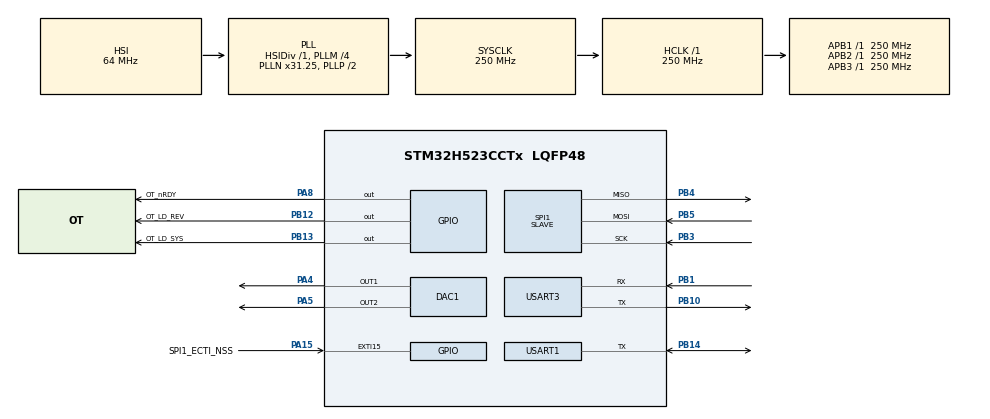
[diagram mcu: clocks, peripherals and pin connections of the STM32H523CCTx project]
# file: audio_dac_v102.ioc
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BOOTPATH.BootPathName=LEGACY
BOOTPATH.UserSelectedBootPath=LEGACY
CORTEX_M33_NS.AccessPermission-Cortex_Memory_Protection_Unit_Region0_Settings=MPU_REGION_ALL_RW
CORTEX_M33_NS.Attributes0=MPU_ATTRIBUTES_NUMBER0
CORTEX_M33_NS.BaseAddress-Cortex_Memory_Protection_Unit_Region0_Settings=0x2003C000
CORTEX_M33_NS.DisableExec-Cortex_Memory_Protection_Unit_Region0_Settings=MPU_INSTRUCTION_ACCESS_DISABLE
CORTEX_M33_NS.Enable-Cortex_Memory_Protection_Unit_Region0_Settings=MPU_REGION_ENABLE
CORTEX_M33_NS.IsShareable-Cortex_Memory_Protection_Unit_Region0_Settings=MPU_ACCESS_INNER_SHAREABLE
CORTEX_M33_NS.LimitAddress-Cortex_Memory_Protection_Unit_Region0_Settings=0x20043FFF
CORTEX_M33_NS.MPU_Control=MPU_PRIVILEGED_DEFAULT
CORTEX_M33_NS.userName=CORTEX_M33
DAC1.DAC_Channel-DAC_OUT1_Ext=DAC_CHANNEL_1
DAC1.DAC_Channel-DAC_OUT2_Ext=DAC_CHANNEL_2
DAC1.DAC_HighFrequency=DAC_HIGH_FREQUENCY_INTERFACE_MODE_DISABLE
DAC1.DAC_Trigger-DAC_OUT1_Ext=DAC_TRIGGER_T1_TRGO
DAC1.DAC_Trigger-DAC_OUT2_Ext=DAC_TRIGGER_T7_TRGO
GPDMA1.CIRCULARMODE_GPDMACH0=ENABLE
GPDMA1.CIRCULARMODE_GPDMACH2=ENABLE
GPDMA1.CIRCULARMODE_GPDMACH4=DISABLE
GPDMA1.DESTINC_GPDMACH0=DMA_DINC_INCREMENTED
GPDMA1.DESTINC_GPDMACH4=DMA_DINC_INCREMENTED
GPDMA1.DIRECTION_GPDMACH1=DMA_MEMORY_TO_PERIPH
GPDMA1.DIRECTION_GPDMACH5=DMA_MEMORY_TO_PERIPH
GPDMA1.IPHANDLE_GPDMACH0-SIMPLEREQUEST_GPDMACH0=__NULL
GPDMA1.IPHANDLE_GPDMACH1-SIMPLEREQUEST_GPDMACH1=__NULL
GPDMA1.IPHANDLE_GPDMACH2-SIMPLEREQUEST_GPDMACH2=__NULL
GPDMA1.IPHANDLE_GPDMACH3-SIMPLEREQUEST_GPDMACH3=__NULL
GPDMA1.IPHANDLE_GPDMACH4-SIMPLEREQUEST_GPDMACH4=__NULL
GPDMA1.IPHANDLE_GPDMACH5-SIMPLEREQUEST_GPDMACH5=__NULL
GPDMA1.REQUEST_GPDMACH0=GPDMA1_REQUEST_USART3_RX
GPDMA1.REQUEST_GPDMACH1=GPDMA1_REQUEST_USART3_TX
GPDMA1.REQUEST_GPDMACH2=GPDMA1_REQUEST_USART1_RX
GPDMA1.REQUEST_GPDMACH3=GPDMA1_REQUEST_USART1_TX
GPDMA1.REQUEST_GPDMACH4=GPDMA1_REQUEST_SPI1_RX
GPDMA1.REQUEST_GPDMACH5=GPDMA1_REQUEST_SPI1_TX
GPDMA1.SRCINC_GPDMACH1=DMA_SINC_INCREMENTED
GPDMA1.SRCINC_GPDMACH5=DMA_SINC_INCREMENTED
GPDMA2.CIRCULARMODE_GPDMACH0=ENABLE
GPDMA2.CIRCULARMODE_GPDMACH1=ENABLE
GPDMA2.DESTDATAWIDTH_GPDMACH0=DMA_DEST_DATAWIDTH_WORD
GPDMA2.DESTDATAWIDTH_GPDMACH1=DMA_DEST_DATAWIDTH_WORD
GPDMA2.DIRECTION_GPDMACH0=DMA_MEMORY_TO_PERIPH
GPDMA2.DIRECTION_GPDMACH1=DMA_MEMORY_TO_PERIPH
GPDMA2.IPHANDLE_GPDMACH0-SIMPLEREQUEST_GPDMACH0=__NULL
GPDMA2.IPHANDLE_GPDMACH1-SIMPLEREQUEST_GPDMACH1=__NULL
GPDMA2.LINKALLOCATEDPORT_CIRCULAR_GPDMACH0=DMA_LINK_ALLOCATED_PORT1
GPDMA2.LINKALLOCATEDPORT_CIRCULAR_GPDMACH1=DMA_LINK_ALLOCATED_PORT1
GPDMA2.PRIORITY_LL_CIRCULAR_GPDMACH0=DMA_LOW_PRIORITY_HIGH_WEIGHT
GPDMA2.PRIORITY_LL_CIRCULAR_GPDMACH1=DMA_LOW_PRIORITY_HIGH_WEIGHT
GPDMA2.REQUEST_GPDMACH0=GPDMA2_REQUEST_DAC1_CH1
GPDMA2.REQUEST_GPDMACH1=GPDMA2_REQUEST_DAC1_CH2
GPDMA2.SRCDATAWIDTH_GPDMACH0=DMA_SRC_DATAWIDTH_HALFWORD
GPDMA2.SRCDATAWIDTH_GPDMACH1=DMA_SRC_DATAWIDTH_HALFWORD
GPDMA2.SRCINC_GPDMACH0=DMA_SINC_INCREMENTED
GPDMA2.SRCINC_GPDMACH1=DMA_SINC_INCREMENTED
GPDMA2.TRANSFERALLOCATEDPORTSRC_GPDMACH0=DMA_SRC_ALLOCATED_PORT1
GPDMA2.TRANSFERALLOCATEDPORTSRC_GPDMACH1=DMA_SRC_ALLOCATED_PORT1
Mcu.Family=STM32H5
Mcu.Name=STM32H523CCTx
Mcu.Package=LQFP48
NVIC.EXTI15_IRQn=true\:0\:0\:false\:false\:true\:true\:true\:true
NVIC.GPDMA1_Channel0_IRQn=true\:2\:0\:true\:false\:true\:false\:true\:true
NVIC.GPDMA1_Channel1_IRQn=true\:2\:0\:true\:false\:true\:false\:true\:true
NVIC.GPDMA1_Channel2_IRQn=true\:2\:0\:true\:false\:true\:false\:true\:true
NVIC.GPDMA1_Channel3_IRQn=true\:2\:0\:true\:false\:true\:false\:true\:true
NVIC.GPDMA1_Channel4_IRQn=true\:2\:0\:true\:false\:true\:false\:true\:true
NVIC.GPDMA1_Channel5_IRQn=true\:2\:0\:true\:false\:true\:false\:true\:true
NVIC.GPDMA2_Channel0_IRQn=true\:0\:0\:false\:false\:true\:false\:true\:true
NVIC.GPDMA2_Channel1_IRQn=true\:0\:0\:false\:false\:true\:false\:true\:true
NVIC.PriorityGroup=NVIC_PRIORITYGROUP_4
NVIC.SPI1_IRQn=true\:1\:0\:true\:false\:true\:true\:true\:true
NVIC.TIM7_IRQn=true\:2\:0\:true\:false\:true\:true\:true\:true
NVIC.USART1_IRQn=true\:1\:0\:true\:false\:true\:true\:true\:true
NVIC.USART3_IRQn=true\:1\:0\:true\:false\:true\:true\:true\:true
PA13(JTMS/SWDIO).Mode=Serial_Wire
PA13(JTMS/SWDIO).Signal=DEBUG_JTMS-SWDIO
PA14(JTCK/SWCLK).Mode=Serial_Wire
PA14(JTCK/SWCLK).Signal=DEBUG_JTCK-SWCLK
PA15(JTDI).GPIO_Label=SPI1_ECTI_NSS
PA15(JTDI).GPIO_ModeDefaultEXTI=GPIO_MODE_IT_RISING_FALLING
PA15(JTDI).Signal=GPXTI15
PA4.Signal=COMP_DAC11_group
PA5.Signal=COMP_DAC12_group
PA8.GPIO_Label=OT_nRDY
PA8.PinState=GPIO_PIN_SET
PA8.Signal=GPIO_Output
PB1.GPIO_PuPd=GPIO_PULLUP
PB1.Mode=Asynchronous
PB1.Signal=USART3_RX
PB10.GPIO_PuPd=GPIO_PULLUP
PB10.Mode=Asynchronous
PB10.Signal=USART3_TX
PB12.GPIO_Label=OT_LD_REV
PB12.Signal=GPIO_Output
PB13.GPIO_Label=OT_LD_SYS
PB13.Signal=GPIO_Output
PB14.GPIO_PuPd=GPIO_PULLUP
PB14.Mode=Half_duplex(single_wire_mode)
PB14.Signal=USART1_TX
PB3(JTDO/TRACESWO).Mode=Full_Duplex_Slave
PB3(JTDO/TRACESWO).Signal=SPI1_SCK
PB4(NJTRST).Mode=Full_Duplex_Slave
PB4(NJTRST).Signal=SPI1_MISO
PB5.Mode=Full_Duplex_Slave
PB5.Signal=SPI1_MOSI
ProjectManager.HeapSize=0x2000
ProjectManager.StackSize=0x2000
ProjectManager.TargetToolchain=STM32CubeIDE
RCC.ADCFreq_Value=250000000
RCC.AHBFreq_Value=250000000
RCC.APB1Freq_Value=250000000
RCC.APB1TimFreq_Value=250000000
RCC.APB2Freq_Value=250000000
RCC.APB2TimFreq_Value=250000000
RCC.APB3Freq_Value=250000000
RCC.CSI_VALUE=4000000
RCC.CortexFreq_Value=250000000
RCC.DACLowPowerCLockSelection=RCC_DACLPCLKSOURCE_LSI
RCC.EPOD_VALUE=64000000
RCC.HCLKFreq_Value=250000000
RCC.HSE_VALUE=25000000
RCC.HSI48_VALUE=48000000
RCC.HSIDiv=RCC_HSI_DIV1
RCC.HSI_VALUE=64000000
RCC.LSE_VALUE=32768
RCC.LSIRC_VALUE=32000
RCC.PLL2M=8
RCC.PLL2N=64
RCC.PLL2Source=RCC_PLL2_SOURCE_HSI
RCC.PLL3M=8
RCC.PLL3N=32
RCC.PLL3P=4
RCC.PLL3Q=4
RCC.PLL3Source=RCC_PLL3_SOURCE_HSI
RCC.PLLFRACN=2048
RCC.PLLM=4
RCC.PLLN=31
RCC.PLLSourceVirtual=RCC_PLL1_SOURCE_HSI
RCC.SPI1CLockSelection=RCC_SPI1CLKSOURCE_PLL3P
RCC.SYSCLKFreq_VALUE=250000000
RCC.SYSCLKSource=RCC_SYSCLKSOURCE_PLLCLK
RCC.USBFreq_Value=48000000
RCC.VCOOutputFreq_Value=500000000
SH.COMP_DAC11_group.0=DAC1_OUT1,DAC_OUT1_Ext
SH.COMP_DAC12_group.0=DAC1_OUT2,DAC_OUT2_Ext
SPI1.DataSize=SPI_DATASIZE_8BIT
SPI1.Direction=SPI_DIRECTION_2LINES
SPI1.FifoThreshold=SPI_FIFO_THRESHOLD_01DATA
SPI1.Mode=SPI_MODE_SLAVE
SPI1.VirtualType=VM_SLAVE
TIM1.PeriodNoDither=7811
TIM1.TIM_MasterOutputTrigger=TIM_TRGO_UPDATE
TIM7.AutoReloadPreload=TIM_AUTORELOAD_PRELOAD_DISABLE
TIM7.PeriodNoDither=7811
TIM7.Prescaler=0
TIM7.TIM_MasterOutputTrigger=TIM_TRGO_UPDATE
USART1.VirtualMode-Half_duplex(single_wire_mode)=VM_ASYNC
USART3.VirtualMode-Asynchronous=VM_ASYNC
VP_BOOTPATH_VS_BOOTPATH.Mode=BP_Activate
VP_CORTEX_M33_NS_VS_Hclk.Mode=Hclk_Mode
VP_DCACHE1_VS_DCACHE.Mode=DCACHE_Activate
VP_GPDMA1_VS_GPDMACH0.Mode=SIMPLEREQUEST_GPDMACH0
VP_GPDMA1_VS_GPDMACH1.Mode=SIMPLEREQUEST_GPDMACH1
VP_GPDMA1_VS_GPDMACH2.Mode=SIMPLEREQUEST_GPDMACH2
VP_GPDMA1_VS_GPDMACH3.Mode=SIMPLEREQUEST_GPDMACH3
VP_GPDMA1_VS_GPDMACH4.Mode=SIMPLEREQUEST_GPDMACH4
VP_GPDMA1_VS_GPDMACH5.Mode=SIMPLEREQUEST_GPDMACH5
VP_GPDMA2_VS_GPDMACH0.Mode=SIMPLEREQUEST_GPDMACH0
VP_GPDMA2_VS_GPDMACH1.Mode=SIMPLEREQUEST_GPDMACH1
VP_ICACHE_VS_ICACHE.Mode=DefaultMode
VP_MEMORYMAP_VS_MEMORYMAP.Mode=CurAppReg
VP_PWR_VS_LPOM.Mode=PowerOptimisation
VP_PWR_VS_SECSignals.Mode=Security/Privilege
VP_TIM1_VS_ClockSourceINT.Mode=Internal
VP_TIM7_VS_ClockSourceINT.Mode=Enable_Timer
board=custom

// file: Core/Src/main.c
/* USER CODE BEGIN Header */
/**
  ******************************************************************************
  * @file           : main.c
  * @brief          : Main program body
  ******************************************************************************
  * @attention
  *
  * Copyright (c) 2025 STMicroelectronics.
  * All rights reserved.
  *
  * This software is licensed under terms that can be found in the LICENSE file
  * in the root directory of this software component.
  * If no LICENSE file comes with this software, it is provided AS-IS.
  *
  ******************************************************************************
  */
/* USER CODE END Header */
#include "main.h"

/* USER CODE BEGIN Includes */
#include "stdio.h"
#include "user_def.h"
/* USER CODE END Includes */

DAC_HandleTypeDef hdac1;
DMA_NodeTypeDef Node_GPDMA2_Channel1;
DMA_QListTypeDef List_GPDMA2_Channel1;
DMA_HandleTypeDef handle_GPDMA2_Channel1;
DMA_NodeTypeDef Node_GPDMA2_Channel0;
DMA_QListTypeDef List_GPDMA2_Channel0;
DMA_HandleTypeDef handle_GPDMA2_Channel0;

DCACHE_HandleTypeDef hdcache1;

SPI_HandleTypeDef hspi1;
DMA_HandleTypeDef handle_GPDMA1_Channel5;
DMA_HandleTypeDef handle_GPDMA1_Channel4;

TIM_HandleTypeDef htim1;
TIM_HandleTypeDef htim7;

UART_HandleTypeDef huart1;
UART_HandleTypeDef huart3;
DMA_HandleTypeDef handle_GPDMA1_Channel3;
DMA_NodeTypeDef Node_GPDMA1_Channel2;
DMA_QListTypeDef List_GPDMA1_Channel2;
DMA_HandleTypeDef handle_GPDMA1_Channel2;
DMA_HandleTypeDef handle_GPDMA1_Channel1;
DMA_NodeTypeDef Node_GPDMA1_Channel0;
DMA_QListTypeDef List_GPDMA1_Channel0;
DMA_HandleTypeDef handle_GPDMA1_Channel0;

void SystemClock_Config(void);
static void MPU_Config(void);
static void MX_GPIO_Init(void);
static void MX_GPDMA1_Init(void);
static void MX_GPDMA2_Init(void);
static void MX_DAC1_Init(void);
static void MX_DCACHE1_Init(void);
static void MX_ICACHE_Init(void);
static void MX_SPI1_Init(void);
static void MX_USART3_UART_Init(void);
static void MX_USART1_UART_Init(void);
static void MX_TIM7_Init(void);
static void MX_TIM1_Init(void);

int main(void)
{

  /* USER CODE BEGIN 1 */
  // MPU disabled - causes SPI reception issues
  /* USER CODE END 1 */

  /* MCU Configuration--------------------------------------------------------*/

  /* MPU Configuration--------------------------------------------------------*/
  MPU_Config();

  /* Reset of all peripherals, Initializes the Flash interface and the Systick. */
  HAL_Init();

  /* Configure the system clock */
  SystemClock_Config();

  /* Initialize all configured peripherals */
  MX_GPIO_Init();
  MX_GPDMA1_Init();
  MX_GPDMA2_Init();
  MX_DAC1_Init();
  MX_DCACHE1_Init();
  MX_ICACHE_Init();
  MX_SPI1_Init();
  MX_USART3_UART_Init();
  MX_USART1_UART_Init();
  MX_TIM7_Init();
  MX_TIM1_Init();
  /* USER CODE BEGIN 2 */
  run_proc();

  /* USER CODE END 2 */

  /* Infinite loop */
  while (1)
  {

  }
}

void SystemClock_Config(void)
{
  RCC_OscInitTypeDef RCC_OscInitStruct = {0};
  RCC_ClkInitTypeDef RCC_ClkInitStruct = {0};

  /** Configure the main internal regulator output voltage
  */
  __HAL_PWR_VOLTAGESCALING_CONFIG(PWR_REGULATOR_VOLTAGE_SCALE0);

  while(!__HAL_PWR_GET_FLAG(PWR_FLAG_VOSRDY)) {}

  /** Initializes the RCC Oscillators according to the specified parameters
  * in the RCC_OscInitTypeDef structure.
  */
  RCC_OscInitStruct.OscillatorType = RCC_OSCILLATORTYPE_HSI|RCC_OSCILLATORTYPE_LSI;
  RCC_OscInitStruct.HSIState = RCC_HSI_ON;
  RCC_OscInitStruct.HSIDiv = RCC_HSI_DIV1;
  RCC_OscInitStruct.HSICalibrationValue = RCC_HSICALIBRATION_DEFAULT;
  RCC_OscInitStruct.LSIState = RCC_LSI_ON;
  RCC_OscInitStruct.PLL.PLLState = RCC_PLL_ON;
  RCC_OscInitStruct.PLL.PLLSource = RCC_PLL1_SOURCE_HSI;
  RCC_OscInitStruct.PLL.PLLM = 4;
  RCC_OscInitStruct.PLL.PLLN = 31;
  RCC_OscInitStruct.PLL.PLLP = 2;
  RCC_OscInitStruct.PLL.PLLQ = 2;
  RCC_OscInitStruct.PLL.PLLR = 2;
  RCC_OscInitStruct.PLL.PLLRGE = RCC_PLL1_VCIRANGE_3;
  RCC_OscInitStruct.PLL.PLLVCOSEL = RCC_PLL1_VCORANGE_WIDE;
  RCC_OscInitStruct.PLL.PLLFRACN = 2048;
  if (HAL_RCC_OscConfig(&RCC_OscInitStruct) != HAL_OK)
  {
    Error_Handler();
  }

  /** Initializes the CPU, AHB and APB buses clocks
  */
  RCC_ClkInitStruct.ClockType = RCC_CLOCKTYPE_HCLK|RCC_CLOCKTYPE_SYSCLK
                              |RCC_CLOCKTYPE_PCLK1|RCC_CLOCKTYPE_PCLK2
                              |RCC_CLOCKTYPE_PCLK3;
  RCC_ClkInitStruct.SYSCLKSource = RCC_SYSCLKSOURCE_PLLCLK;
  RCC_ClkInitStruct.AHBCLKDivider = RCC_SYSCLK_DIV1;
  RCC_ClkInitStruct.APB1CLKDivider = RCC_HCLK_DIV1;
  RCC_ClkInitStruct.APB2CLKDivider = RCC_HCLK_DIV1;
  RCC_ClkInitStruct.APB3CLKDivider = RCC_HCLK_DIV1;

  if (HAL_RCC_ClockConfig(&RCC_ClkInitStruct, FLASH_LATENCY_5) != HAL_OK)
  {
    Error_Handler();
  }

  /** Configure the programming delay
  */
  __HAL_FLASH_SET_PROGRAM_DELAY(FLASH_PROGRAMMING_DELAY_2);
}

static void MX_DAC1_Init(void)
{

  DAC_ChannelConfTypeDef sConfig = {0};

  /* USER CODE BEGIN DAC1_Init 1 */
  sConfig.DAC_OutputBuffer = DAC_OUTPUTBUFFER_ENABLE;

  /* USER CODE END DAC1_Init 1 */

  /** DAC Initialization
  */
  hdac1.Instance = DAC1;
  if (HAL_DAC_Init(&hdac1) != HAL_OK)
  {
    Error_Handler();
  }

  /** DAC channel OUT1 config
  */
  sConfig.DAC_HighFrequency = DAC_HIGH_FREQUENCY_INTERFACE_MODE_AUTOMATIC;
  sConfig.DAC_DMADoubleDataMode = DISABLE;
  sConfig.DAC_SignedFormat = DISABLE;
  sConfig.DAC_SampleAndHold = DAC_SAMPLEANDHOLD_DISABLE;
  sConfig.DAC_Trigger = DAC_TRIGGER_T1_TRGO;
  sConfig.DAC_OutputBuffer = DAC_OUTPUTBUFFER_ENABLE;
  sConfig.DAC_ConnectOnChipPeripheral = DAC_CHIPCONNECT_EXTERNAL;
  sConfig.DAC_UserTrimming = DAC_TRIMMING_FACTORY;
  if (HAL_DAC_ConfigChannel(&hdac1, &sConfig, DAC_CHANNEL_1) != HAL_OK)
  {
    Error_Handler();
  }

  /** DAC channel OUT2 config
  */
  sConfig.DAC_HighFrequency = DAC_HIGH_FREQUENCY_INTERFACE_MODE_AUTOMATIC;
  sConfig.DAC_DMADoubleDataMode = DISABLE;
  sConfig.DAC_SignedFormat = DISABLE;
  sConfig.DAC_SampleAndHold = DAC_SAMPLEANDHOLD_DISABLE;
  // DAC CH2 uses TIM7 TRGO trigger
  sConfig.DAC_Trigger = DAC_TRIGGER_T7_TRGO;  // TSEL=6 → TIM7 TRGO
  sConfig.DAC_OutputBuffer = DAC_OUTPUTBUFFER_ENABLE;
  sConfig.DAC_ConnectOnChipPeripheral = DAC_CHIPCONNECT_EXTERNAL;
  sConfig.DAC_UserTrimming = DAC_TRIMMING_FACTORY;
  if (HAL_DAC_ConfigChannel(&hdac1, &sConfig, DAC_CHANNEL_2) != HAL_OK)
  {
    Error_Handler();
  }

  /* USER CODE BEGIN DAC1_Init 1.5 */
  // INDEPENDENT DAC MODE: Each channel has its own DMA and trigger
  // DAC1: TEN1=1, DMAEN1=1, TSEL1=0 (TIM1_TRGO)
  // DAC2: TEN2=1, DMAEN2=1, TSEL2=6 (TIM7_TRGO)
  // Both channels operate independently with their own sample rates

  printf("[DAC_INIT] INDEPENDENT MODE: CH1=TIM1, CH2=TIM7, CR=0x%08lX\r\n", DAC1->CR);
  /* USER CODE END DAC1_Init 1.5 */
  /* USER CODE BEGIN DAC1_Init 2 */

  // NOTE: Calibration is performed in user_def.c init_proc() after UART init

  /* USER CODE END DAC1_Init 2 */

}

static void MX_DCACHE1_Init(void)
{

  hdcache1.Instance = DCACHE1;
  hdcache1.Init.ReadBurstType = DCACHE_READ_BURST_WRAP;
  if (HAL_DCACHE_Init(&hdcache1) != HAL_OK)
  {
    Error_Handler();
  }

}

static void MX_GPDMA1_Init(void)
{

  /* Peripheral clock enable */
  __HAL_RCC_GPDMA1_CLK_ENABLE();

  /* GPDMA1 interrupt Init */
    HAL_NVIC_SetPriority(GPDMA1_Channel0_IRQn, 2, 0);
    HAL_NVIC_EnableIRQ(GPDMA1_Channel0_IRQn);
    HAL_NVIC_SetPriority(GPDMA1_Channel1_IRQn, 2, 0);
    HAL_NVIC_EnableIRQ(GPDMA1_Channel1_IRQn);
    HAL_NVIC_SetPriority(GPDMA1_Channel2_IRQn, 2, 0);
    HAL_NVIC_EnableIRQ(GPDMA1_Channel2_IRQn);
    HAL_NVIC_SetPriority(GPDMA1_Channel3_IRQn, 2, 0);
    HAL_NVIC_EnableIRQ(GPDMA1_Channel3_IRQn);
    HAL_NVIC_SetPriority(GPDMA1_Channel4_IRQn, 2, 0);
    HAL_NVIC_EnableIRQ(GPDMA1_Channel4_IRQn);
    HAL_NVIC_SetPriority(GPDMA1_Channel5_IRQn, 2, 0);
    HAL_NVIC_EnableIRQ(GPDMA1_Channel5_IRQn);

}

static void MX_GPDMA2_Init(void)
{

  /* Peripheral clock enable */
  __HAL_RCC_GPDMA2_CLK_ENABLE();

  /* GPDMA2 interrupt Init */
    HAL_NVIC_SetPriority(GPDMA2_Channel0_IRQn, 0, 0);
    HAL_NVIC_EnableIRQ(GPDMA2_Channel0_IRQn);
    HAL_NVIC_SetPriority(GPDMA2_Channel1_IRQn, 0, 0);
    HAL_NVIC_EnableIRQ(GPDMA2_Channel1_IRQn);

}

static void MX_ICACHE_Init(void)
{

  /** Enable instruction cache (default 2-ways set associative cache)
  */
  if (HAL_ICACHE_Enable() != HAL_OK)
  {
    Error_Handler();
  }

}

static void MX_SPI1_Init(void)
{

  /* SPI1 parameter configuration*/
  hspi1.Instance = SPI1;
  hspi1.Init.Mode = SPI_MODE_SLAVE;
  hspi1.Init.Direction = SPI_DIRECTION_2LINES;
  hspi1.Init.DataSize = SPI_DATASIZE_8BIT;
  hspi1.Init.CLKPolarity = SPI_POLARITY_LOW;
  hspi1.Init.CLKPhase = SPI_PHASE_1EDGE;
  hspi1.Init.NSS = SPI_NSS_SOFT;
  hspi1.Init.FirstBit = SPI_FIRSTBIT_MSB;
  hspi1.Init.TIMode = SPI_TIMODE_DISABLE;
  hspi1.Init.CRCCalculation = SPI_CRCCALCULATION_DISABLE;
  hspi1.Init.CRCPolynomial = 0x7;
  hspi1.Init.NSSPMode = SPI_NSS_PULSE_DISABLE;
  hspi1.Init.NSSPolarity = SPI_NSS_POLARITY_LOW;
  hspi1.Init.FifoThreshold = SPI_FIFO_THRESHOLD_01DATA;
  hspi1.Init.MasterSSIdleness = SPI_MASTER_SS_IDLENESS_00CYCLE;
  hspi1.Init.MasterInterDataIdleness = SPI_MASTER_INTERDATA_IDLENESS_00CYCLE;
  hspi1.Init.MasterReceiverAutoSusp = SPI_MASTER_RX_AUTOSUSP_DISABLE;
  hspi1.Init.MasterKeepIOState = SPI_MASTER_KEEP_IO_STATE_DISABLE;
  hspi1.Init.IOSwap = SPI_IO_SWAP_DISABLE;
  hspi1.Init.ReadyMasterManagement = SPI_RDY_MASTER_MANAGEMENT_INTERNALLY;
  hspi1.Init.ReadyPolarity = SPI_RDY_POLARITY_HIGH;
  if (HAL_SPI_Init(&hspi1) != HAL_OK)
  {
    Error_Handler();
  }

}

static void MX_TIM1_Init(void)
{

  TIM_ClockConfigTypeDef sClockSourceConfig = {0};
  TIM_MasterConfigTypeDef sMasterConfig = {0};

  htim1.Instance = TIM1;
  htim1.Init.Prescaler = 0;
  htim1.Init.CounterMode = TIM_COUNTERMODE_UP;
  htim1.Init.Period = 7811;
  htim1.Init.ClockDivision = TIM_CLOCKDIVISION_DIV1;
  htim1.Init.RepetitionCounter = 0;
  htim1.Init.AutoReloadPreload = TIM_AUTORELOAD_PRELOAD_DISABLE;
  if (HAL_TIM_Base_Init(&htim1) != HAL_OK)
  {
    Error_Handler();
  }
  sClockSourceConfig.ClockSource = TIM_CLOCKSOURCE_INTERNAL;
  if (HAL_TIM_ConfigClockSource(&htim1, &sClockSourceConfig) != HAL_OK)
  {
    Error_Handler();
  }
  sMasterConfig.MasterOutputTrigger = TIM_TRGO_UPDATE;
  sMasterConfig.MasterOutputTrigger2 = TIM_TRGO2_RESET;
  sMasterConfig.MasterSlaveMode = TIM_MASTERSLAVEMODE_DISABLE;
  if (HAL_TIMEx_MasterConfigSynchronization(&htim1, &sMasterConfig) != HAL_OK)
  {
    Error_Handler();
  }

}

static void MX_TIM7_Init(void)
{

  TIM_MasterConfigTypeDef sMasterConfig = {0};

  htim7.Instance = TIM7;
  htim7.Init.Prescaler = 0;
  htim7.Init.CounterMode = TIM_COUNTERMODE_UP;
  htim7.Init.Period = 7811;
  htim7.Init.AutoReloadPreload = TIM_AUTORELOAD_PRELOAD_DISABLE;
  if (HAL_TIM_Base_Init(&htim7) != HAL_OK)
  {
    Error_Handler();
  }
  sMasterConfig.MasterOutputTrigger = TIM_TRGO_UPDATE;
  sMasterConfig.MasterSlaveMode = TIM_MASTERSLAVEMODE_DISABLE;
  if (HAL_TIMEx_MasterConfigSynchronization(&htim7, &sMasterConfig) != HAL_OK)
  {
    Error_Handler();
  }

}

static void MX_USART1_UART_Init(void)
{

  huart1.Instance = USART1;
  huart1.Init.BaudRate = 115200;
  huart1.Init.WordLength = UART_WORDLENGTH_8B;
  huart1.Init.StopBits = UART_STOPBITS_1;
  huart1.Init.Parity = UART_PARITY_NONE;
  huart1.Init.Mode = UART_MODE_TX_RX;
  huart1.Init.HwFlowCtl = UART_HWCONTROL_NONE;
  huart1.Init.OverSampling = UART_OVERSAMPLING_16;
  huart1.Init.OneBitSampling = UART_ONE_BIT_SAMPLE_DISABLE;
  huart1.Init.ClockPrescaler = UART_PRESCALER_DIV1;
  huart1.AdvancedInit.AdvFeatureInit = UART_ADVFEATURE_NO_INIT;
  if (HAL_HalfDuplex_Init(&huart1) != HAL_OK)
  {
    Error_Handler();
  }
  if (HAL_UARTEx_SetTxFifoThreshold(&huart1, UART_TXFIFO_THRESHOLD_1_8) != HAL_OK)
  {
    Error_Handler();
  }
  if (HAL_UARTEx_SetRxFifoThreshold(&huart1, UART_RXFIFO_THRESHOLD_1_8) != HAL_OK)
  {
    Error_Handler();
  }
  if (HAL_UARTEx_DisableFifoMode(&huart1) != HAL_OK)
  {
    Error_Handler();
  }

}

static void MX_USART3_UART_Init(void)
{

  huart3.Instance = USART3;
  huart3.Init.BaudRate = 115200;
  huart3.Init.WordLength = UART_WORDLENGTH_8B;
  huart3.Init.StopBits = UART_STOPBITS_1;
  huart3.Init.Parity = UART_PARITY_NONE;
  huart3.Init.Mode = UART_MODE_TX_RX;
  huart3.Init.HwFlowCtl = UART_HWCONTROL_NONE;
  huart3.Init.OverSampling = UART_OVERSAMPLING_16;
  huart3.Init.OneBitSampling = UART_ONE_BIT_SAMPLE_DISABLE;
  huart3.Init.ClockPrescaler = UART_PRESCALER_DIV1;
  huart3.AdvancedInit.AdvFeatureInit = UART_ADVFEATURE_NO_INIT;
  if (HAL_UART_Init(&huart3) != HAL_OK)
  {
    Error_Handler();
  }
  if (HAL_UARTEx_SetTxFifoThreshold(&huart3, UART_TXFIFO_THRESHOLD_1_8) != HAL_OK)
  {
    Error_Handler();
  }
  if (HAL_UARTEx_SetRxFifoThreshold(&huart3, UART_RXFIFO_THRESHOLD_1_8) != HAL_OK)
  {
    Error_Handler();
  }
  if (HAL_UARTEx_DisableFifoMode(&huart3) != HAL_OK)
  {
    Error_Handler();
  }

}

static void MX_GPIO_Init(void)
{
  GPIO_InitTypeDef GPIO_InitStruct = {0};

  /* GPIO Ports Clock Enable */
  __HAL_RCC_GPIOA_CLK_ENABLE();
  __HAL_RCC_GPIOB_CLK_ENABLE();

  /*Configure GPIO pin Output Level */
  HAL_GPIO_WritePin(GPIOB, OT_LD_REV_Pin|OT_LD_SYS_Pin, GPIO_PIN_RESET);

  /*Configure GPIO pin Output Level */
  HAL_GPIO_WritePin(OT_nRDY_GPIO_Port, OT_nRDY_Pin, GPIO_PIN_SET);

  /*Configure GPIO pins : OT_LD_REV_Pin OT_LD_SYS_Pin */
  GPIO_InitStruct.Pin = OT_LD_REV_Pin|OT_LD_SYS_Pin;
  GPIO_InitStruct.Mode = GPIO_MODE_OUTPUT_PP;
  GPIO_InitStruct.Pull = GPIO_NOPULL;
  GPIO_InitStruct.Speed = GPIO_SPEED_FREQ_LOW;
  HAL_GPIO_Init(GPIOB, &GPIO_InitStruct);

  /*Configure GPIO pin : OT_nRDY_Pin */
  GPIO_InitStruct.Pin = OT_nRDY_Pin;
  GPIO_InitStruct.Mode = GPIO_MODE_OUTPUT_PP;
  GPIO_InitStruct.Pull = GPIO_NOPULL;
  GPIO_InitStruct.Speed = GPIO_SPEED_FREQ_LOW;
  HAL_GPIO_Init(OT_nRDY_GPIO_Port, &GPIO_InitStruct);

  /*Configure GPIO pin : SPI1_ECTI_NSS_Pin */
  GPIO_InitStruct.Pin = SPI1_ECTI_NSS_Pin;
  GPIO_InitStruct.Mode = GPIO_MODE_IT_RISING_FALLING;
  GPIO_InitStruct.Pull = GPIO_NOPULL;
  HAL_GPIO_Init(SPI1_ECTI_NSS_GPIO_Port, &GPIO_InitStruct);

  /* EXTI interrupt init*/
  HAL_NVIC_SetPriority(EXTI15_IRQn, 0, 0);
  HAL_NVIC_EnableIRQ(EXTI15_IRQn);

  /* USER CODE BEGIN MX_GPIO_Init_2 */

  // PA15: Software NSS + EXTI (IT mode)
  // Falling edge: CS LOW -> Start SPI IT reception
  // Rising edge: CS HIGH -> Transmission complete
  printf("[GPIO] PA15 = SPI1_EXT_NSS (Software NSS + EXTI, IT mode)\r\n");
  printf("[NVIC] EXTI15 interrupt enabled (priority 1)\r\n");

  /* USER CODE END MX_GPIO_Init_2 */
}

 /* MPU Configuration */

void MPU_Config(void)
{
  MPU_Region_InitTypeDef MPU_InitStruct = {0};
  MPU_Attributes_InitTypeDef MPU_AttributesInit = {0};

  /* Disables the MPU */
  HAL_MPU_Disable();

  /** Initializes and configures the Region 0 and the memory to be protected
  */
  MPU_InitStruct.Enable = MPU_REGION_ENABLE;
  MPU_InitStruct.Number = MPU_REGION_NUMBER0;
  MPU_InitStruct.BaseAddress = 0x2003C000;
  MPU_InitStruct.LimitAddress = 0x20043FFF;
  MPU_InitStruct.AttributesIndex = MPU_ATTRIBUTES_NUMBER0;
  MPU_InitStruct.AccessPermission = MPU_REGION_ALL_RW;
  MPU_InitStruct.DisableExec = MPU_INSTRUCTION_ACCESS_DISABLE;
  MPU_InitStruct.IsShareable = MPU_ACCESS_INNER_SHAREABLE;

  HAL_MPU_ConfigRegion(&MPU_InitStruct);

  /** Initializes and configures the Attribute 0 and the memory to be protected
  */
  MPU_AttributesInit.Number = MPU_ATTRIBUTES_NUMBER0;
  MPU_AttributesInit.Attributes = INNER_OUTER(MPU_NOT_CACHEABLE);

  HAL_MPU_ConfigMemoryAttributes(&MPU_AttributesInit);
  /* Enables the MPU */
  HAL_MPU_Enable(MPU_PRIVILEGED_DEFAULT);

}

void Error_Handler(void)
{
  __disable_irq();
  while (1)
  {
  }
}
